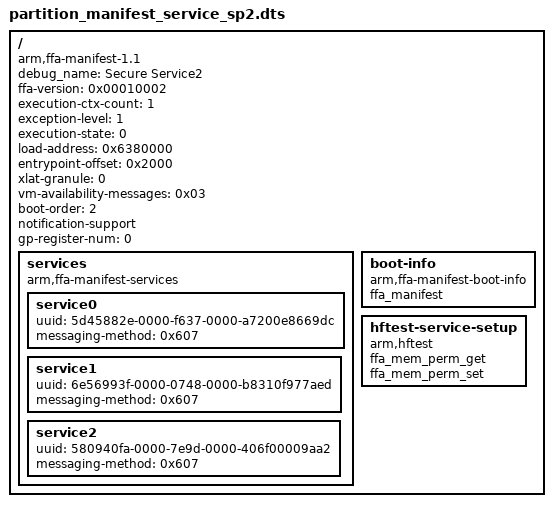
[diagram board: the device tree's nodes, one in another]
/*
 * Copyright 2023 The Hafnium Authors.
 *
 * Use of this source code is governed by a BSD-style
 * license that can be found in the LICENSE file or at
 * https://opensource.org/licenses/BSD-3-Clause.
 */

/dts-v1/;

/ {
	compatible = "arm,ffa-manifest-1.1";
	debug_name = "Secure Service2";

	/* Properties */
	ffa-version = <0x00010002>; /* 31:16 - Major, 15:0 - Minor */
	execution-ctx-count = <1>;
	exception-level = <1>; /* S-EL0 */
	execution-state = <0>; /* AARCH64 */
	load-address = <0x6380000>;
	entrypoint-offset = <0x2000>;
	xlat-granule = <0>; /* 4KiB */
	vm-availability-messages = <0x03>; /* Supports VM created and VM destroyed messages. */
	boot-order = <2>;
	notification-support; /* Receipt of notifications. */
	gp-register-num = <0>;

	services {
		compatible = "arm,ffa-manifest-services";

		service0 {
			uuid = "5d45882e-0000-f637-0000-a7200e8669dc";
			messaging-method = <0x607>; /* Supports direct (both APIs) and indirect requests. */
		};

		service1 {
			uuid = "6e56993f-0000-0748-0000-b8310f977aed";
			messaging-method = <0x607>;
		};

		service2 {
			uuid = "580940fa-0000-7e9d-0000-406f00009aa2"; /* EL0 service uuid. */
			messaging-method = <0x607>;
		};
	};

	/* Boot Info */
	boot-info {
		compatible = "arm,ffa-manifest-boot-info";
		ffa_manifest;
	};

	hftest-service-setup {
		compatible = "arm,hftest";
		ffa_mem_perm_get;
		ffa_mem_perm_set;
	};
};
